# CY8C4A45LQI_483 register map
File version: 0.1
PSoC Analog Coprocessor
Registers are 32-bit, read-write, no defined reset value unless marked. A register's access mark holds for its fields unless they carry their own. Offsets are from the block's base; lines under a group give offsets from that group; [hi:lo] are bit positions; {n}, {i} and the like mark numbered series; 'fields as' and 'values as' point back to an identical list; <NAME> marks a mode.

## Memory map
0x00000000 RefBuffer — OpAmp
0x00000000 I2C_1 — Serial Communication Block
0x00000000 Opamp_TIA — OpAmp
0x00000000 EZI2C — Serial Communication Block
0x00000000 ADC
0x00000000 PWM
0x40000000 DMAC — DMAC Registers

## RefBuffer — OpAmp
Base 0x00000000
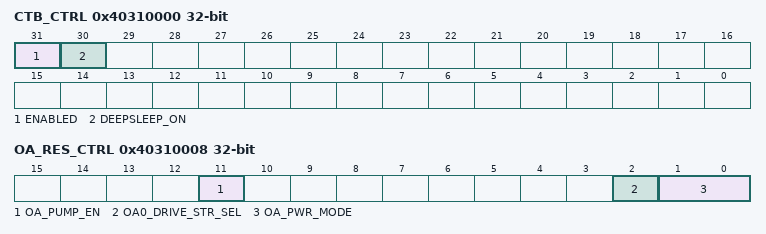
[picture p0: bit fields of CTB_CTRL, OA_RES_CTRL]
0x40310000 CTB_CTRL — Global CTB IP and power control
  [31] ENABLED — Selects component behavior in DeepSleep power mode
    0=DISABLE (CTB IP disabled (put analog in power down, open all switches)); 1=ENABLE (CTB IP enabledCTB IP enabled)
  [30] DEEPSLEEP_ON — Selects component behavior in DeepSleep power mode
    0=DISABLE (CTB IP disabled off during DeepSleep power mode); 1=ENABLE (CTB IP remains enabled during DeepSleep power mode (if ENABLED=1))
0x40310008 OA_RES_CTRL — Opamp and resistor control
  [11] OA_PUMP_EN — Selects pump
    0=DISABLE (Pump disabled); 1=ENABLE (Pump enabled)
  [2] OA0_DRIVE_STR_SEL — Opamp output strenght select
    0=Cy1x (Internal only); 1=Cy10x (Output to pin)
  [1:0] OA_PWR_MODE — Selects power for opamp
    0=OFF; 1=LOW (Low power); 2=MED (Medium power); 3=HIGH (High power)
0x40310F14 OA_COMP_TRIM — Opamp Compenation Capacitor Trim
  [1:0] OA_COMP_TRIM
    1=HIGH_SPEED; 2=BALANCED; 3=HIGH_STABILITY

## Opamp_TIA — OpAmp
Base 0x00000000
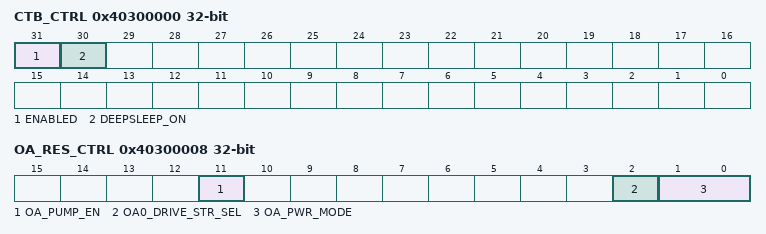
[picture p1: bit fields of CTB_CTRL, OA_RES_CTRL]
0x40300000 CTB_CTRL — Global CTB IP and power control
  [31] ENABLED — Selects component behavior in DeepSleep power mode
    0=DISABLE (CTB IP disabled (put analog in power down, open all switches)); 1=ENABLE (CTB IP enabledCTB IP enabled)
  [30] DEEPSLEEP_ON — Selects component behavior in DeepSleep power mode
    0=DISABLE (CTB IP disabled off during DeepSleep power mode); 1=ENABLE (CTB IP remains enabled during DeepSleep power mode (if ENABLED=1))
0x40300008 OA_RES_CTRL — Opamp and resistor control
  [11] OA_PUMP_EN — Selects pump
    0=DISABLE (Pump disabled); 1=ENABLE (Pump enabled)
  [2] OA0_DRIVE_STR_SEL — Opamp output strenght select
    0=Cy1x (Internal only); 1=Cy10x (Output to pin)
  [1:0] OA_PWR_MODE — Selects power for opamp
    0=OFF; 1=LOW (Low power); 2=MED (Medium power); 3=HIGH (High power)
0x40300F14 OA_COMP_TRIM — Opamp Compenation Capacitor Trim
  [1:0] OA_COMP_TRIM
    1=HIGH_SPEED; 2=BALANCED; 3=HIGH_STABILITY

## PWM
Base 0x00000000
0x40010188 COUNTER — Current counter value
0x4001018C CC — Compare / capture value
0x40010190 CC_BUF — Compare / capture buffer value
0x40010194 PERIOD — Period value
0x40010198 PERIOD_BUF — Period buffer value
